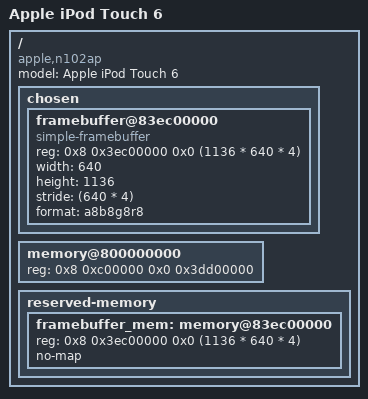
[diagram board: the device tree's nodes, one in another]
// SPDX-License-Identifier: GPL-2.0+ OR MIT
/*
 * Apple iPod Touch 6, N102AP, iPod7,1 (A1574)
 * Copyright (c) 2022, Konrad Dybcio <konrad.dybcio@somainline.org>
 */

/dts-v1/;

#include "t7000.dtsi"

/ {
	model = "Apple iPod Touch 6";
	compatible = "apple,n102ap", "apple,t7000", "apple,arm-platform";

	chosen {
		framebuffer@83ec00000 {
			compatible = "simple-framebuffer";
			reg = <0x8 0x3ec00000 0x0 (1136 * 640 * 4)>;
			width = <640>;
			height = <1136>;
			stride = <(640 * 4)>;
			format = "a8b8g8r8";
		};
	};

	/*
	 * iPod 6 has 1GB ram.
	 * Currently PongoOs doesn't fill in the memory node, so keep it in DT.
	 */
	memory@800000000 {
		device_type = "memory";
		reg = <0x8 0xc00000 0x0 0x3dd00000>;
	};

	reserved-memory {
		framebuffer_mem: memory@83ec00000 {
			reg = <0x8 0x3ec00000 0x0 (1136 * 640 * 4)>;
			no-map;
		};
	};
};
